AUTOSAR XML (schema 4-2-2)
package /Components
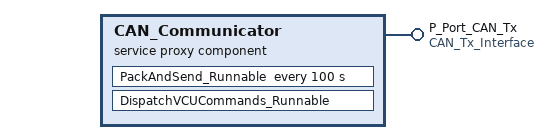
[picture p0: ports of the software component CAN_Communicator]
  service proxy sw component type CAN_Communicator
    provide port P_Port_CAN_Tx: provided-interface=CAN_Tx_Interface
    5 x provide/require port:
      R_Port_SOC: provided-required-interface=SOC_Interface
      R_Port_SOH: provided-required-interface=SOC_Interface
      R_Port_SafetyEvents: provided-required-interface=Safety_Interface
      R_Port_CellSummary: provided-required-interface=CellVoltage_Interface
      PR_Port_ChargeService: provided-required-interface=Charge_Interface
    behavior CAN_Communicator_Behavior
      data received event VCU_Command_Received: start-on-event=DispatchVCUCommands_Runnable
      timing event Can_Heartbeat_100ms: start-on-event=PackAndSend_Runnable, period=100
      runnable PackAndSend_Runnable: minimum-start-interval=100, symbol=CAN_Communicator_PackAndSend
        data-receive-point-by-arguments:
          4 x access:
            Read_SOC: accessed-variable=R_Port_SOC.SOC
            Read_SOH: accessed-variable=R_Port_SOH.SOH
            Read_SafetyEvent: accessed-variable=R_Port_SafetyEvents.safetyEvent
            Read_CellSummary: accessed-variable=R_Port_CellSummary.cellVoltageSummary
        data-receive-point-by-values:
          access Prepare_CAN_Frame: accessed-variable=P_Port_CAN_Tx.CAN_Frame
        async call ChargeRequest_Call: operation=PR_Port_ChargeService.ChargeRequest, timeout=200
      runnable DispatchVCUCommands_Runnable: minimum-start-interval=10, symbol=CAN_Communicator_DispatchVCU
        data-receive-point-by-arguments:
          access Receive_CAN_Frame_Arg: accessed-variable=P_Port_CAN_Tx.CAN_Frame
        data-receive-point-by-values:
          access Parse_And_Dispatch: accessed-variable=P_Port_CAN_Tx.CAN_Frame
        async call Dispatch_ChargeRequest: operation=PR_Port_ChargeService.ChargeRequest, timeout=200
